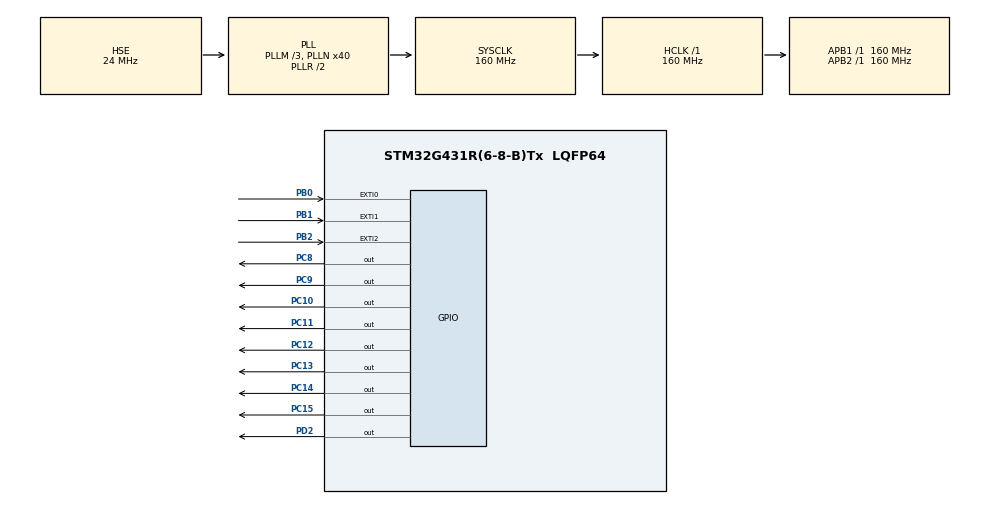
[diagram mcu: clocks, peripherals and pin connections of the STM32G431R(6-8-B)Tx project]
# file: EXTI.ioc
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Mcu.Family=STM32G4
Mcu.Name=STM32G431R(6-8-B)Tx
Mcu.Package=LQFP64
NVIC.EXTI0_IRQn=true\:0\:0\:false\:false\:true\:true\:true
NVIC.EXTI1_IRQn=true\:0\:0\:false\:false\:true\:true\:true
NVIC.EXTI2_IRQn=true\:0\:0\:false\:false\:true\:true\:true
NVIC.PriorityGroup=NVIC_PRIORITYGROUP_4
PA13.Mode=Serial_Wire
PA13.Signal=SYS_JTMS-SWDIO
PA14.Mode=Serial_Wire
PA14.Signal=SYS_JTCK-SWCLK
PB0.GPIO_ModeDefaultEXTI=GPIO_MODE_IT_RISING
PB0.Signal=GPXTI0
PB1.GPIO_ModeDefaultEXTI=GPIO_MODE_IT_FALLING
PB1.Signal=GPXTI1
PB2.GPIO_ModeDefaultEXTI=GPIO_MODE_IT_RISING_FALLING
PB2.Signal=GPXTI2
PC10.Signal=GPIO_Output
PC11.Signal=GPIO_Output
PC12.Signal=GPIO_Output
PC13.Signal=GPIO_Output
PC14-OSC32_IN.Signal=GPIO_Output
PC15-OSC32_OUT.Signal=GPIO_Output
PC8.Signal=GPIO_Output
PC9.Signal=GPIO_Output
PD2.Signal=GPIO_Output
PF0-OSC_IN.Mode=HSE-External-Oscillator
PF0-OSC_IN.Signal=RCC_OSC_IN
PF1-OSC_OUT.Mode=HSE-External-Oscillator
PF1-OSC_OUT.Signal=RCC_OSC_OUT
ProjectManager.HeapSize=0x200
ProjectManager.StackSize=0x400
ProjectManager.TargetToolchain=MDK-ARM V5.27
RCC.ADC12Freq_Value=160000000
RCC.AHBFreq_Value=160000000
RCC.APB1Freq_Value=160000000
RCC.APB1TimFreq_Value=160000000
RCC.APB2Freq_Value=160000000
RCC.APB2TimFreq_Value=160000000
RCC.CortexFreq_Value=160000000
RCC.EXTERNAL_CLOCK_VALUE=12288000
RCC.HCLKFreq_Value=160000000
RCC.HSE_VALUE=24000000
RCC.HSI48_VALUE=48000000
RCC.HSI_VALUE=16000000
RCC.LSE_VALUE=32768
RCC.PLLM=RCC_PLLM_DIV3
RCC.PLLN=40
RCC.PLLSourceVirtual=RCC_PLLSOURCE_HSE
RCC.SYSCLKFreq_VALUE=160000000
RCC.SYSCLKSource=RCC_SYSCLKSOURCE_PLLCLK
RCC.USBFreq_Value=160000000
RCC.VCOOutputFreq_Value=320000000
VP_SYS_VS_DBSignals.Mode=DisableDeadBatterySignals
board=custom

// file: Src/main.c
/* USER CODE BEGIN Header */
/**
  ******************************************************************************
  * @file           : main.c
  * @brief          : Main program body
  ******************************************************************************
  * @attention
  *
  * <h2><center>&copy; Copyright (c) 2023 STMicroelectronics.
  * All rights reserved.</center></h2>
  *
  * This software component is licensed by ST under BSD 3-Clause license,
  * the "License"; You may not use this file except in compliance with the
  * License. You may obtain a copy of the License at:
  *                        opensource.org/licenses/BSD-3-Clause
  *
  ******************************************************************************
  */
/* USER CODE END Header */

#include "main.h"
#include "gpio.h"

/* USER CODE BEGIN Includes */
#include "lcd_hal.h"
/* USER CODE END Includes */

void SystemClock_Config(void);

int main(void)
{

  /* MCU Configuration--------------------------------------------------------*/

  /* Reset of all peripherals, Initializes the Flash interface and the Systick. */
  HAL_Init();

  /* Configure the system clock */
  SystemClock_Config();

  /* Initialize all configured peripherals */
  MX_GPIO_Init();

  /* Infinite loop */
  while (1)
  {

  }
}

void SystemClock_Config(void)
{
  RCC_OscInitTypeDef RCC_OscInitStruct = {0};
  RCC_ClkInitTypeDef RCC_ClkInitStruct = {0};

  /** Configure the main internal regulator output voltage
  */
  HAL_PWREx_ControlVoltageScaling(PWR_REGULATOR_VOLTAGE_SCALE1_BOOST);
  /** Initializes the CPU, AHB and APB busses clocks
  */
  RCC_OscInitStruct.OscillatorType = RCC_OSCILLATORTYPE_HSE;
  RCC_OscInitStruct.HSEState = RCC_HSE_ON;
  RCC_OscInitStruct.PLL.PLLState = RCC_PLL_ON;
  RCC_OscInitStruct.PLL.PLLSource = RCC_PLLSOURCE_HSE;
  RCC_OscInitStruct.PLL.PLLM = RCC_PLLM_DIV3;
  RCC_OscInitStruct.PLL.PLLN = 40;
  RCC_OscInitStruct.PLL.PLLP = RCC_PLLP_DIV2;
  RCC_OscInitStruct.PLL.PLLQ = RCC_PLLQ_DIV2;
  RCC_OscInitStruct.PLL.PLLR = RCC_PLLR_DIV2;
  if (HAL_RCC_OscConfig(&RCC_OscInitStruct) != HAL_OK)
  {
    Error_Handler();
  }
  /** Initializes the CPU, AHB and APB busses clocks
  */
  RCC_ClkInitStruct.ClockType = RCC_CLOCKTYPE_HCLK|RCC_CLOCKTYPE_SYSCLK
                              |RCC_CLOCKTYPE_PCLK1|RCC_CLOCKTYPE_PCLK2;
  RCC_ClkInitStruct.SYSCLKSource = RCC_SYSCLKSOURCE_PLLCLK;
  RCC_ClkInitStruct.AHBCLKDivider = RCC_SYSCLK_DIV1;
  RCC_ClkInitStruct.APB1CLKDivider = RCC_HCLK_DIV1;
  RCC_ClkInitStruct.APB2CLKDivider = RCC_HCLK_DIV1;

  if (HAL_RCC_ClockConfig(&RCC_ClkInitStruct, FLASH_LATENCY_7) != HAL_OK)
  {
    Error_Handler();
  }
}

void Error_Handler(void)
{
}

/************************ (C) COPYRIGHT STMicroelectronics *****END OF FILE****/
